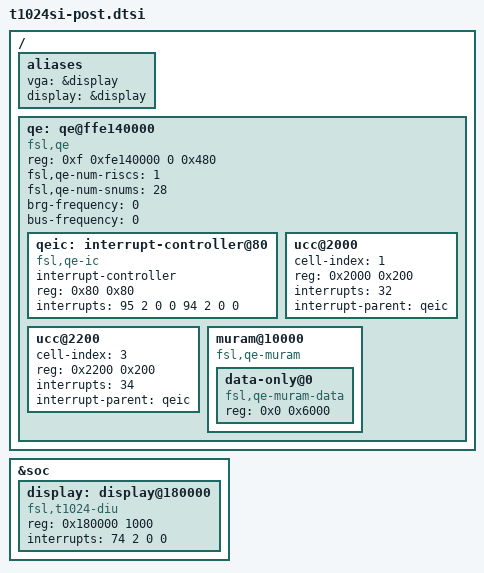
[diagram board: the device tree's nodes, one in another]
/*
 * T1024 Silicon/SoC Device Tree Source (post include)
 *
 * Copyright 2014 Freescale Semiconductor Inc.
 *
 * Redistribution and use in source and binary forms, with or without
 * modification, are permitted provided that the following conditions are met:
 *     * Redistributions of source code must retain the above copyright
 *       notice, this list of conditions and the following disclaimer.
 *     * Redistributions in binary form must reproduce the above copyright
 *       notice, this list of conditions and the following disclaimer in the
 *       documentation and/or other materials provided with the distribution.
 *     * Neither the name of Freescale Semiconductor nor the
 *       names of its contributors may be used to endorse or promote products
 *       derived from this software without specific prior written permission.
 *
 *
 * ALTERNATIVELY, this software may be distributed under the terms of the
 * GNU General Public License ("GPL") as published by the Free Software
 * Foundation, either version 2 of that License or (at your option) any
 * later version.
 *
 * THIS SOFTWARE IS PROVIDED BY Freescale Semiconductor "AS IS" AND ANY
 * EXPRESS OR IMPLIED WARRANTIES, INCLUDING, BUT NOT LIMITED TO, THE IMPLIED
 * WARRANTIES OF MERCHANTABILITY AND FITNESS FOR A PARTICULAR PURPOSE ARE
 * DISCLAIMED. IN NO EVENT SHALL Freescale Semiconductor BE LIABLE FOR ANY
 * DIRECT, INDIRECT, INCIDENTAL, SPECIAL, EXEMPLARY, OR CONSEQUENTIAL DAMAGES
 * (INCLUDING, BUT NOT LIMITED TO, PROCUREMENT OF SUBSTITUTE GOODS OR SERVICES;
 * LOSS OF USE, DATA, OR PROFITS; OR BUSINESS INTERRUPTION) HOWEVER CAUSED AND
 * ON ANY THEORY OF LIABILITY, WHETHER IN CONTRACT, STRICT LIABILITY, OR TORT
 * (INCLUDING NEGLIGENCE OR OTHERWISE) ARISING IN ANY WAY OUT OF THE USE OF THIS
 * SOFTWARE, EVEN IF ADVISED OF THE POSSIBILITY OF SUCH DAMAGE.
 */

#include "t1023si-post.dtsi"

/ {
	aliases {
		vga = &display;
		display = &display;
	};

	qe:qe@ffe140000 {
		#address-cells = <1>;
		#size-cells = <1>;
		device_type = "qe";
		compatible = "fsl,qe";
		ranges = <0x0 0xf 0xfe140000 0x40000>;
		reg = <0xf 0xfe140000 0 0x480>;
		fsl,qe-num-riscs = <1>;
		fsl,qe-num-snums = <28>;
		brg-frequency = <0>;
		bus-frequency = <0>;
	};
};

&soc {
	display:display@180000 {
		compatible = "fsl,t1024-diu", "fsl,diu";
		reg = <0x180000 1000>;
		interrupts = <74 2 0 0>;
	};
};

&qe {
	qeic: interrupt-controller@80 {
		interrupt-controller;
		compatible = "fsl,qe-ic";
		#address-cells = <0>;
		#interrupt-cells = <1>;
		reg = <0x80 0x80>;
		interrupts = <95 2 0 0  94 2 0 0>; //high:79 low:78
	};

	ucc@2000 {
		cell-index = <1>;
		reg = <0x2000 0x200>;
		interrupts = <32>;
		interrupt-parent = <&qeic>;
	};

	ucc@2200 {
		cell-index = <3>;
		reg = <0x2200 0x200>;
		interrupts = <34>;
		interrupt-parent = <&qeic>;
	};

	muram@10000 {
		#address-cells = <1>;
		#size-cells = <1>;
		compatible = "fsl,qe-muram", "fsl,cpm-muram";
		ranges = <0x0 0x10000 0x6000>;

		data-only@0 {
			compatible = "fsl,qe-muram-data", "fsl,cpm-muram-data";
			reg = <0x0 0x6000>;
		};
	};
};
